# STM32G564 register map
File version: 2.0.0
CPU: CM33 r0p4, little endian, MPU, FPU, 4 interrupt priority bits
Registers are 32-bit, read-write, reset 0x0 unless marked. A register's access mark holds for its fields unless they carry their own. Offsets are from the block's base; [hi:lo] are bit positions; 'fields as' and 'values as' point back to an identical list.

## XSPI1 — XSPI register block
Base 0x47001400
Same registers: XSPI1_S 0x57001400
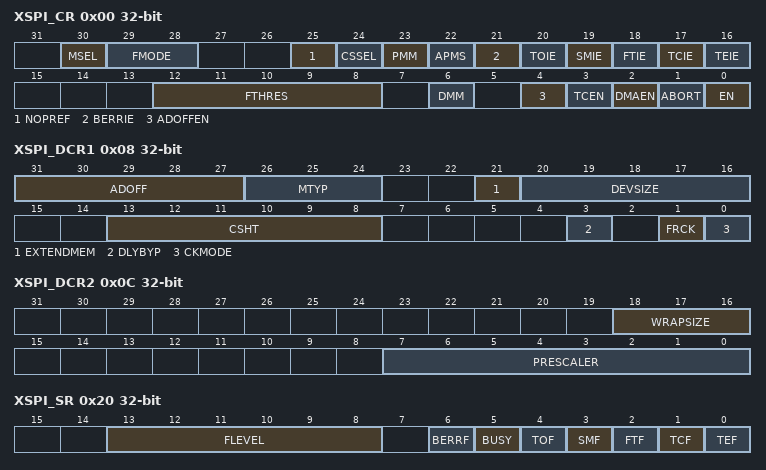
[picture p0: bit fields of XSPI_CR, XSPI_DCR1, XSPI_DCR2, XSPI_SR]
0x00 XSPI_CR — XSPI control register
  [30] MSEL — External memory select
    0=External memory 1 selected (data exchanged over IO[3:0]); 1=External memory 2 selected (data exchanged over IO[7:4])
  [29:28] FMODE — Functional mode
    0=Indirect-write mode; 1=Indirect-read mode; 2=Automatic status-polling mode (relevant in regular-command protocol only); 3=Memory-mapped mode
  [25] NOPREF — No prefetch data
    0=Automatic prefetch enabled; 1=Automatic prefetch disabled
  [24] CSSEL — Chip-select selection
    0=NCS1 active; 1=NCS2 active
  [23] PMM — Polling match mode
    0=AND-match mode, SMF is set if all the unmasked bits received from the device match the corresponding bits in the match register; 1=OR-match mode, SMF is set if any of the unmasked bits received from the device matches its corresponding bit in the match register
  [22] APMS — Automatic status-polling mode stop
    0=Automatic status-polling mode is stopped only by abort or by disabling the XSPI; 1=Automatic status-polling mode stops as soon as there is a match
  [21] BERRIE — Bus error interrupt enable
    0=Interrupt disabled; 1=Interrupt enabled
  [20] TOIE — Timeout interrupt enable
    0=Interrupt disabled; 1=Interrupt enabled
  [19] SMIE — Status-match interrupt enable
    0=Interrupt disabled; 1=Interrupt enabled
  [18] FTIE — FIFO threshold interrupt enable
    0=Interrupt disabled; 1=Interrupt enabled
  [17] TCIE — Transfer complete interrupt enable
    0=Interrupt disabled; 1=Interrupt enabled
  [16] TEIE — Transfer error interrupt enable
    0=Interrupt disabled; 1=Interrupt enabled
  [12:8] FTHRES — FIFO threshold level
    0=FTF is set if there are one or more free bytes available to be written to in the FIFO inindirect-write mode, or if there are one or more valid bytes can be read from the FIFO inindirect-read mode; 1=FTF is set if there are two or more free bytes available to be written to in the FIFO inindirect-write mode, or if there are two or more valid bytes can be read from the FIFO inindirect-read mode; 31=FTF is set if there are 32 free bytes available to be written to in the FIFO in indirect-write mode, or if there are 32 valid bytes can be read from the FIFO in indirect-read mode
  [6] DMM — Dual-memory configuration
    0=Dual-memory configuration disabled; 1=Dual-memory configuration enabled
  [4] ADOFFEN — Address offset enable
    0=Address offset disabled; 1=Address offset enabled
  [3] TCEN — Timeout counter enable
    0=The timeout counter is disabled, and thus the chip-select (NCS) remains active indefinitely after an access in memory-mapped mode; 1=The timeout counter is enabled, and thus the chip-select is released in the memory-mapped mode after TIMEOUT[15:0] cycles of external device inactivity
  [2] DMAEN — DMA enable
    0=DMA disabled for indirect mode; 1=DMA enabled for indirect mode
  [1] ABORT — Abort request
    0=No abort requested; 1=Abort requested
  [0] EN — Enable
    0=XSPI disabled; 1=XSPI enabled
0x08 XSPI_DCR1 — XSPI device configuration register 1
  [31:27] ADOFF — Address offset
  [26:24] MTYP — Memory type
    0=Micron mode, D0/D1 ordering in DTR 8-data-bit mode. regular-command protocol in single-, dual-, quad- and octal-SPI modes.; 1=Macronix mode, D1/D0 ordering in DTR 8-data-bit mode. Regular-command protocol; 2=Standard mode; 3=Macronix RAM mode, D1/D0 ordering in DTR 8-data-bit mode. Regular-command protocol in single-, dual-, quad-, and octal-SPI modes with dedicated address mapping (address is built with row and column to fit with Macronix requirements).; 4=HyperBus memory mode, the protocol follows the HyperBusless thansup> less than/sup>specification; 5=HyperBus register mode, addressing register space. The memory-mapped accesses in this mode must be noncacheable, or indirect-read/write modes must be used.
  [21] EXTENDMEM — Extended memory support
    0=NCS1 and NCS2 values depend from CSSEL bit in XSPI_CR (software controlled); 1=NCS1 and NCS2 values depend from the address of transfer (hardware controlled)
  [20:16] DEVSIZE — Device size
  [13:8] CSHT — Chip-select high time
    0=NCS stays high for at least 1 cycle between external device commands; 1=NCS stays high for at least 2 cycles between external device commands; 63=NCS stays high for at least 64 cycles between external device commands
  [3] DLYBYP — Delay block bypass
    0=The internal sampling clock (called feedback clock) or the DQS data strobe external signal is delayed by the delay block (for more details on this block, refer to the dedicated section of the reference manual as it is not part of the peripheral); 1=The delay block is bypassed, so the internal sampling clock or the DQS data strobe external signal is not affected by the delay block. The delay is shorter than when the delay block is not bypassed, even with the delay value set to minimum value in delay block.
  [1] FRCK — Free running clock
    0=CLK is not free running; 1=CLK is free running (always provided)
  [0] CKMODE — Clock mode 0
0x0C XSPI_DCR2 — XSPI device configuration register 2
  [18:16] WRAPSIZE
    0=Wrapped reads are not supported by the memory; 2=External memory supports wrap size of 16 bytes; 3=External memory supports wrap size of 32 bytes; 4=External memory supports wrap size of 64 bytes; 5=External memory supports wrap size of 128 bytes
  [7:0] PRESCALER — Clock prescaler
    0=FCLK = FKERNEL, kernel clock used directly as XSPI CLK (prescaler bypassed). In this case, if the DTR mode is used, it is mandatory to provide to the XSPI a kernel clock that has 50% duty-cycle.; 1=FCLK = FKERNEL/2
0x10 XSPI_DCR3 — XSPI device configuration register 3
  [20:16] CSBOUND — NCS boundary
    0=NCS boundary disabled
0x14 XSPI_DCR4 — XSPI device configuration register 4
  [31:0] REFRESH — Refresh rate
    0=Refresh disabled
0x20 XSPI_SR ro — XSPI status register
  [13:8] FLEVEL — FIFO level
  [6] BERRF — Bus error flag
  [5] BUSY
  [4] TOF — Timeout flag
  [3] SMF — Status match flag
  [2] FTF — FIFO threshold flag
  [1] TCF — Transfer complete flag
  [0] TEF — Transfer error flag
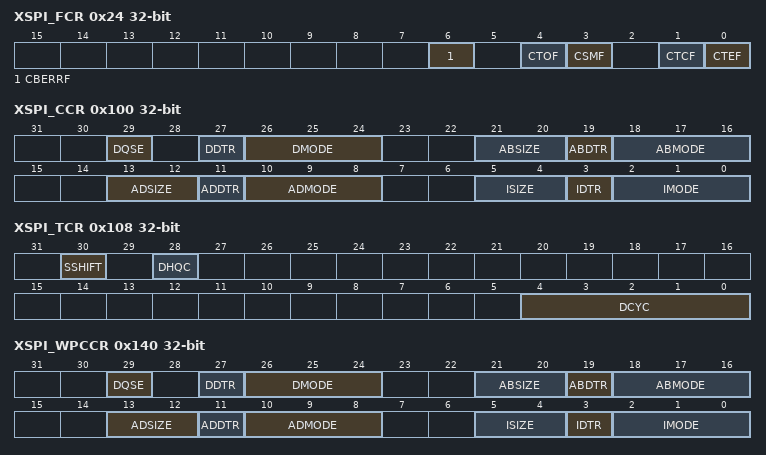
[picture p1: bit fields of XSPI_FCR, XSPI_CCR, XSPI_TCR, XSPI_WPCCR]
0x24 XSPI_FCR wo — XSPI flag clear register
  [6] CBERRF — Clear bus error flag
  [4] CTOF — Clear timeout flag
  [3] CSMF — Clear status match flag
  [1] CTCF — Clear transfer complete flag
  [0] CTEF — Clear transfer error flag
0x40 XSPI_DLR — XSPI data length register
  [31:0] DL — Data length
0x48 XSPI_AR — XSPI address register
  [31:0] ADDRESS
0x50 XSPI_DR — XSPI data register
  [31:0] DATA
0x80 XSPI_PSMKR — XSPI polling status mask register
  [31:0] MASK — Status mask
    0=Bit n of the data received in automatic status-polling mode is masked and its value is not considered in the matching logic; 1=Bit n of the data received in automatic status-polling mode is unmasked and its value is considered in the matching logic
0x88 XSPI_PSMAR — XSPI polling status match register
  [31:0] MATCH — Status match
0x90 XSPI_PIR — XSPI polling interval register
  [15:0] INTERVAL — Polling interval
0x100 XSPI_CCR — XSPI communication configuration register
  [29] DQSE — DQS enable
    0=DQS disabled; 1=DQS enabled
  [27] DDTR — Data double transfer rate
    0=DTR mode disabled for data phase; 1=DTR mode enabled for data phase
  [26:24] DMODE — Data mode
    0=No data; 1=Data on a single line; 2=Data on two lines; 3=Data on four lines; 4=Data on eight lines
  [21:20] ABSIZE — Alternate-byte size
    0=8-bit alternate bytes; 1=16-bit alternate bytes; 2=24-bit alternate bytes; 3=32-bit alternate bytes
  [19] ABDTR — Alternate- byte double transfer rate
    0=DTR mode disabled for the alternate-byte phase; 1=DTR mode enabled for the alternate-byte phase
  [18:16] ABMODE — Alternate-byte mode
    0=No alternate bytes; 1=Alternate bytes on a single line; 2=Alternate bytes on two lines; 3=Alternate bytes on four lines; 4=Alternate bytes on eight lines
  [13:12] ADSIZE — Address size
    0=8-bit address; 1=16-bit address; 2=24-bit address; 3=32-bit address
  [11] ADDTR — Address double transfer rate
    0=DTR mode disabled for the address phase; 1=DTR mode enabled for the address phase
  [10:8] ADMODE — Address mode
    0=No address; 1=Address on a single line; 2=Address on two lines; 3=Address on four lines; 4=Address on eight lines
  [5:4] ISIZE — Instruction size
    0=8-bit instruction; 1=16-bit instruction; 2=24-bit instruction; 3=32-bit instruction
  [3] IDTR — Instruction double transfer rate
    0=DTR mode disabled for the instruction phase; 1=DTR mode enabled for the instruction phase
  [2:0] IMODE — Instruction mode
    0=No instruction; 1=Instruction on a single line; 2=Instruction on two lines; 3=Instruction on four lines; 4=Instruction on eight lines
0x108 XSPI_TCR — XSPI timing configuration register
  [30] SSHIFT — Sample shift
    0=No shift; 1=1/2 cycle shift
  [28] DHQC — Delay hold quarter cycle
    0=No delay hold; 1=1/4 cycle hold
  [4:0] DCYC — Number of dummy cycles
0x110 XSPI_IR — XSPI instruction register
  [31:0] INSTRUCTION
0x120 XSPI_ABR — XSPI alternate bytes register
  [31:0] ALTERNATE — Alternate bytes
0x130 XSPI_LPTR — XSPI low-power timeout register
  [15:0] TIMEOUT — Timeout period
0x140 XSPI_WPCCR — XSPI wrap communication configuration register
  [29] DQSE — DQS enable
    0=DQS disabled; 1=DQS enabled
  [27] DDTR — Data double transfer rate
    0=DTR mode disabled for the data phase; 1=DTR mode enabled for the data phase
  [26:24] DMODE — Data mode
    values as XSPI_CCR.DMODE
  [21:20] ABSIZE — Alternate-byte size
    values as XSPI_CCR.ABSIZE
  [19] ABDTR — Alternate-byte double transfer rate
    values as XSPI_CCR.ABDTR
  [18:16] ABMODE — Alternate-byte mode
    0=no alternate bytes; 1=alternate bytes on a single line; 2=alternate bytes on two lines; 3=alternate bytes on four lines; 4=alternate bytes on eight lines
  [13:12] ADSIZE — Address size
    values as XSPI_CCR.ADSIZE
  [11] ADDTR — Address double transfer rate
    0=DTR mode disabled for address phase; 1=DTR mode enabled for address phase
  [10:8] ADMODE — Address mode
    values as XSPI_CCR.ADMODE
  [5:4] ISIZE — Instruction size
    values as XSPI_CCR.ISIZE
  [3] IDTR — Instruction double transfer rate
    values as XSPI_CCR.IDTR
  [2:0] IMODE — Instruction mode
    values as XSPI_CCR.IMODE
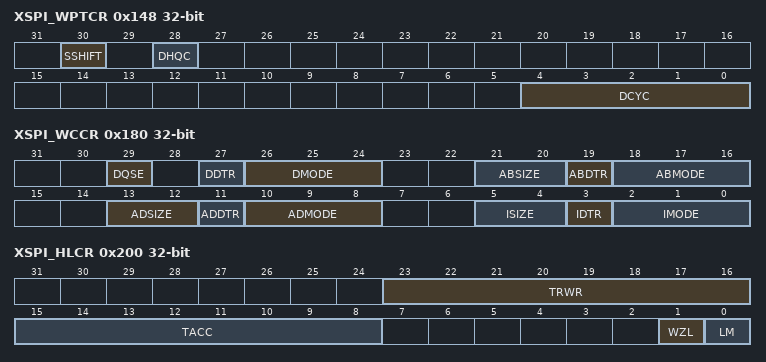
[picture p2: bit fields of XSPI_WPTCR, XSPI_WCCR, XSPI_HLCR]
0x148 XSPI_WPTCR — XSPI wrap timing configuration register
  [30] SSHIFT — Sample shift
    0=No shift; 1=1/2 cycle shift
  [28] DHQC — Delay hold quarter cycle
    0=No quarter cycle delay; 1=1/4 cycle delay inserted
  [4:0] DCYC — Number of dummy cycles
0x150 XSPI_WPIR — XSPI wrap instruction register
  [31:0] INSTRUCTION
0x160 XSPI_WPABR — XSPI wrap alternate bytes register
  [31:0] ALTERNATE — Alternate bytes
0x180 XSPI_WCCR — XSPI write communication configuration register
  [29] DQSE — DQS enable
    0=DQS disabled; 1=DQS enabled
  [27] DDTR — data double transfer rate
    values as XSPI_WPCCR.DDTR
  [26:24] DMODE — Data mode
    values as XSPI_CCR.DMODE
  [21:20] ABSIZE — Alternate-byte size
    values as XSPI_CCR.ABSIZE
  [19] ABDTR — Alternate bytes double transfer rate
    0=DTR mode disabled for alternate-bytes phase; 1=DTR mode enabled for alternate-bytes phase
  [18:16] ABMODE — Alternate-byte mode
    values as XSPI_CCR.ABMODE
  [13:12] ADSIZE — Address size
    values as XSPI_CCR.ADSIZE
  [11] ADDTR — Address double transfer rate
    values as XSPI_CCR.ADDTR
  [10:8] ADMODE — Address mode
    values as XSPI_CCR.ADMODE
  [5:4] ISIZE — Instruction size
    values as XSPI_CCR.ISIZE
  [3] IDTR — Instruction double transfer rate
    0=DTR mode disabled for instruction phase; 1=DTR mode enabled for instruction phase
  [2:0] IMODE — Instruction mode
    values as XSPI_CCR.IMODE
0x188 XSPI_WTCR — XSPI write timing configuration register
  [4:0] DCYC — Number of dummy cycles
0x190 XSPI_WIR — XSPI write instruction register
  [31:0] INSTRUCTION
0x1A0 XSPI_WABR — XSPI write alternate bytes register
  [31:0] ALTERNATE — Alternate bytes
0x200 XSPI_HLCR — XSPI HyperBus latency configuration register
  [23:16] TRWR — Read-write minimum recovery time
  [15:8] TACC — Access time
  [1] WZL — Write zero latency
    0=Latency on write accesses; 1=No latency on write accesses
  [0] LM — Latency mode
    0=Variable initial latency; 1=Fixed latency
